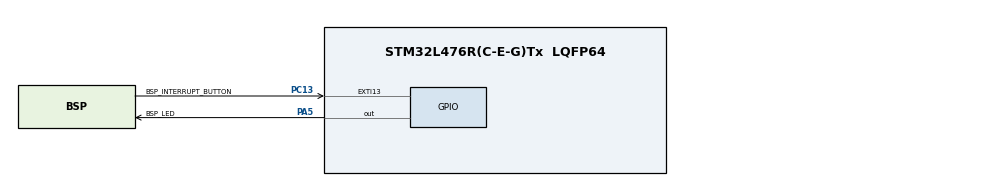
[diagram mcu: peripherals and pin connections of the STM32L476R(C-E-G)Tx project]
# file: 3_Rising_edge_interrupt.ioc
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Mcu.Family=STM32L4
Mcu.Name=STM32L476R(C-E-G)Tx
Mcu.Package=LQFP64
NVIC.EXTI15_10_IRQn=true\:0\:0\:false\:false\:true\:true\:true\:true
NVIC.PriorityGroup=NVIC_PRIORITYGROUP_4
PA5.GPIO_Label=BSP_LED
PA5.GPIO_PuPd=GPIO_PULLDOWN
PA5.Signal=GPIO_Output
PC13.GPIO_Label=BSP_INTERRUPT_BUTTON
PC13.GPIO_ModeDefaultEXTI=GPIO_MODE_IT_FALLING
PC13.GPIO_PuPd=GPIO_PULLUP
PC13.Signal=GPXTI13
ProjectManager.HeapSize=0x200
ProjectManager.StackSize=0x400
ProjectManager.TargetToolchain=STM32CubeIDE
RCC.HSE_VALUE=8000000
RCC.HSI_VALUE=16000000
RCC.LSE_VALUE=32768
RCC.MSI_VALUE=4000000
RCC.VCOOutputFreq_Value=32000000
board=custom

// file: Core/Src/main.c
/* USER CODE BEGIN Header */
/**
  ******************************************************************************
  * @file           : main.c
  * @brief          : Main program body
  ******************************************************************************
  * @attention
  *
  * Copyright (c) 2024 STMicroelectronics.
  * All rights reserved.
  *
  * This software is licensed under terms that can be found in the LICENSE file
  * in the root directory of this software component.
  * If no LICENSE file comes with this software, it is provided AS-IS.
  *
  ******************************************************************************
  */
/* USER CODE END Header */
#include "main.h"

/* USER CODE BEGIN Includes */
#include <stdbool.h>
/* USER CODE END Includes */

/* USER CODE BEGIN PV */
static volatile bool buttonPress = true;
static volatile int buttonPressCount = 0;
/* USER CODE END PV */

void SystemClock_Config(void);
static void MX_GPIO_Init(void);

int main(void)
{

  /* MCU Configuration--------------------------------------------------------*/

  /* Reset of all peripherals, Initializes the Flash interface and the Systick. */
  HAL_Init();

  /* Configure the system clock */
  SystemClock_Config();

  /* Initialize all configured peripherals */
  MX_GPIO_Init();

  /* Infinite loop */
  while (1)
  {

    /* USER CODE BEGIN 3 */
//	  if(buttonPress == false){
//		  for(int i = 0; i < 20; i++){
//	  	  	HAL_GPIO_TogglePin(BSP_LED_GPIO_Port, BSP_LED_Pin);
//	  	  	HAL_Delay(1000);
//		  }
//	  	  	buttonPress = true;  //Reset state
//	  	 }
//  }

	  if (buttonPress == false)
	      {
	        if (buttonPressCount % 2 == 0)
	        {
	          for (int i = 0; i < 20; i++)
	          {
	            HAL_GPIO_TogglePin(BSP_LED_GPIO_Port, BSP_LED_Pin);
	            HAL_Delay(500);
	          }
	        }
	        else
	        {
	          for (int i = 0; i < 20; i++)
	          {
	            HAL_GPIO_TogglePin(BSP_LED_GPIO_Port, BSP_LED_Pin);
	            HAL_Delay(1000);
	          }
	        }
	        buttonPress = true; // Reset state
	      }
	    }
  /* USER CODE END 3 */
}

void SystemClock_Config(void)
{
  RCC_OscInitTypeDef RCC_OscInitStruct = {0};
  RCC_ClkInitTypeDef RCC_ClkInitStruct = {0};

  /** Configure the main internal regulator output voltage
  */
  if (HAL_PWREx_ControlVoltageScaling(PWR_REGULATOR_VOLTAGE_SCALE1) != HAL_OK)
  {
    Error_Handler();
  }

  /** Initializes the RCC Oscillators according to the specified parameters
  * in the RCC_OscInitTypeDef structure.
  */
  RCC_OscInitStruct.OscillatorType = RCC_OSCILLATORTYPE_MSI;
  RCC_OscInitStruct.MSIState = RCC_MSI_ON;
  RCC_OscInitStruct.MSICalibrationValue = 0;
  RCC_OscInitStruct.MSIClockRange = RCC_MSIRANGE_6;
  RCC_OscInitStruct.PLL.PLLState = RCC_PLL_NONE;
  if (HAL_RCC_OscConfig(&RCC_OscInitStruct) != HAL_OK)
  {
    Error_Handler();
  }

  /** Initializes the CPU, AHB and APB buses clocks
  */
  RCC_ClkInitStruct.ClockType = RCC_CLOCKTYPE_HCLK|RCC_CLOCKTYPE_SYSCLK
                              |RCC_CLOCKTYPE_PCLK1|RCC_CLOCKTYPE_PCLK2;
  RCC_ClkInitStruct.SYSCLKSource = RCC_SYSCLKSOURCE_MSI;
  RCC_ClkInitStruct.AHBCLKDivider = RCC_SYSCLK_DIV1;
  RCC_ClkInitStruct.APB1CLKDivider = RCC_HCLK_DIV1;
  RCC_ClkInitStruct.APB2CLKDivider = RCC_HCLK_DIV1;

  if (HAL_RCC_ClockConfig(&RCC_ClkInitStruct, FLASH_LATENCY_0) != HAL_OK)
  {
    Error_Handler();
  }
}

static void MX_GPIO_Init(void)
{
  GPIO_InitTypeDef GPIO_InitStruct = {0};

  /* GPIO Ports Clock Enable */
  __HAL_RCC_GPIOC_CLK_ENABLE();
  __HAL_RCC_GPIOA_CLK_ENABLE();

  /*Configure GPIO pin Output Level */
  HAL_GPIO_WritePin(BSP_LED_GPIO_Port, BSP_LED_Pin, GPIO_PIN_RESET);

  /*Configure GPIO pin : BSP_INTERRUPT_BUTTON_Pin */
  GPIO_InitStruct.Pin = BSP_INTERRUPT_BUTTON_Pin;
  GPIO_InitStruct.Mode = GPIO_MODE_IT_FALLING;
  GPIO_InitStruct.Pull = GPIO_PULLUP;
  HAL_GPIO_Init(BSP_INTERRUPT_BUTTON_GPIO_Port, &GPIO_InitStruct);

  /*Configure GPIO pin : BSP_LED_Pin */
  GPIO_InitStruct.Pin = BSP_LED_Pin;
  GPIO_InitStruct.Mode = GPIO_MODE_OUTPUT_PP;
  GPIO_InitStruct.Pull = GPIO_PULLDOWN;
  GPIO_InitStruct.Speed = GPIO_SPEED_FREQ_LOW;
  HAL_GPIO_Init(BSP_LED_GPIO_Port, &GPIO_InitStruct);

  /* EXTI interrupt init*/
  HAL_NVIC_SetPriority(EXTI15_10_IRQn, 0, 0);
  HAL_NVIC_EnableIRQ(EXTI15_10_IRQn);

}

/* USER CODE BEGIN 4 */
void HAL_GPIO_EXTI_Callback(uint16_t GPIO_Pin)
{
	if(GPIO_Pin == BSP_INTERRUPT_BUTTON_Pin)
	    {
	    	//buttonPress = false ;  // Set State

		    buttonPressCount++; // Increment the button press count
		    buttonPress = false; // Set State
	    }
}
/* USER CODE END 4 */

void Error_Handler(void)
{
  __disable_irq();
  while (1)
  {
  }
}
